# nrf54lv10a_enga_application register map
Vendor: Nordic Semiconductor; Series: nrf54l; File version: 1
CPU: CM33 r0p4, little endian, MPU, FPU, 3 interrupt priority bits, 270 interrupts, 4 SAU regions
Registers are 32-bit, read-write, reset 0x0 unless marked. A register's access mark holds for its fields unless they carry their own. Offsets are from the block's base; [hi:lo] are bit positions; lines under a group give offsets from that group; {n}, {i} and the like mark numbered series; 'fields as' and 'values as' point back to an identical list.

## GLOBAL_ECB00_NS — AES ECB Mode Encryption 0
Base 0x4004B000
Same registers: GLOBAL_ECB00_S 0x5004B000
0x00 TASKS_START wo — Start ECB block encrypt
  [0] TASKS_START
    1=Trigger task
0x04 TASKS_STOP wo — Abort a possible executing ECB operation
  [0] TASKS_STOP
    1=Trigger task
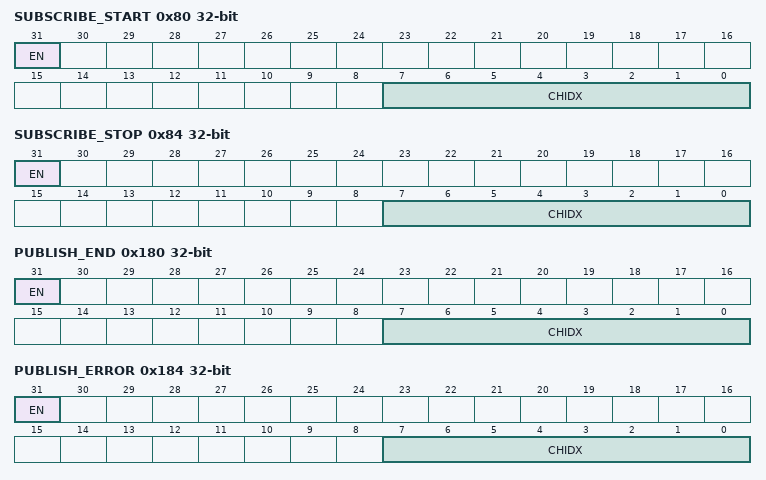
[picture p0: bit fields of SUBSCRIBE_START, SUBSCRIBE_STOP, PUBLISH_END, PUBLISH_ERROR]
0x80 SUBSCRIBE_START — Subscribe configuration for task START
  [31] EN
    0=Disabled (Disable subscription); 1=Enabled (Enable subscription)
  [7:0] CHIDX — DPPI channel that task START will subscribe to
0x84 SUBSCRIBE_STOP — Subscribe configuration for task STOP
  [31] EN
    values as SUBSCRIBE_START.EN
  [7:0] CHIDX — DPPI channel that task STOP will subscribe to
0x100 EVENTS_END — ECB block encrypt complete
  [0] EVENTS_END
    0=NotGenerated (Event not generated); 1=Generated (Event generated)
0x104 EVENTS_ERROR — ECB block encrypt aborted because of a STOP task or due to an error
  [0] EVENTS_ERROR
    values as EVENTS_END.EVENTS_END
0x180 PUBLISH_END — Publish configuration for event END
  [31] EN
    0=Disabled (Disable publishing); 1=Enabled (Enable publishing)
  [7:0] CHIDX — DPPI channel that event END will publish to
0x184 PUBLISH_ERROR — Publish configuration for event ERROR
  [31] EN
    values as PUBLISH_END.EN
  [7:0] CHIDX — DPPI channel that event ERROR will publish to
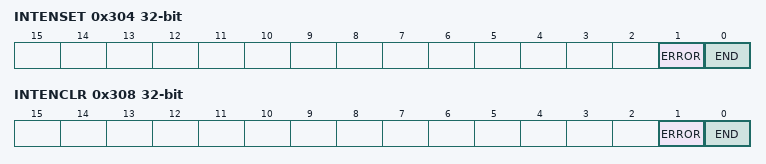
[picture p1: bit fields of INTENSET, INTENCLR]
0x304 INTENSET — Enable interrupt
  [1] ERROR — Write '1' to enable interrupt for event ERROR
    on read: 0=Disabled (Read: Disabled); 1=Enabled (Read: Enabled) | on write: 1=Set (Enable)
  [0] END — Write '1' to enable interrupt for event END
    values as ERROR
0x308 INTENCLR — Disable interrupt
  [1] ERROR — Write '1' to disable interrupt for event ERROR
    on read: 0=Disabled (Read: Disabled); 1=Enabled (Read: Enabled) | on write: 1=Clear (Disable)
  [0] END — Write '1' to disable interrupt for event END
    values as ERROR
0x400 ERRORSTATUS ro
  [2:0] ERRORSTATUS — Error status when the ERROR event is generated
    0=No errors have occurred; 1=PrematureInptrEnd (End of INPTR job list before data structure was read.); 2=PrematureOutptrEnd (End of OUTPTR job list before data structure was read.); 3=EncryptionTooSlow (Deprecated enumerator - Encryption aborted due to higher priority peripheral requesting or using the AES module.); 3=Aborted (Encryption aborted due to higher priority peripheral requesting or using the AES module.); 4=DmaError (Bus error during DMA access.)
0x510 KEY group — Unspecified
  {0x0+4j} VALUE[{j}] (j=0..3) wo — Description collection: 128-bit AES key
    [31:0] VALUE — AES 128-bit key value, bits (32*(n+1))-1 : (32*n)
0x530 IN group — IN EasyDMA channel
  0x00 PTR — Input pointer
    [31:0] PTR — Points to a job list containing unencrypted ECB data structure
0x538 OUT group — OUT EasyDMA channel
  0x00 PTR — Output pointer Points to a job list containing encrypted ECB data structure
    [31:0] PTR — Output pointer
0x53C CSAA group — Channel sounding access address scoring algorithm
  0x00 REFLECTOR ro — Selected Channel Sounding Access Address used in the CS SYNC from Reflector to Initiator
    [31:0] PN
  0x04 INITIATOR ro — Selected Channel Sounding Access Address used in the CS SYNC from Initiator to Reflector
    [31:0] PN
  0x08 MODE — Operation modes
    [0] BITREVERSE — Reverse the endianness on bit level for the ECB output, INITIATOR, and REFLECTOR registers
      0=Default endianness; 1=Reversed endianness

## GLOBAL_GLITCHDET_S — Voltage glitch detectors
Base 0x5004E000
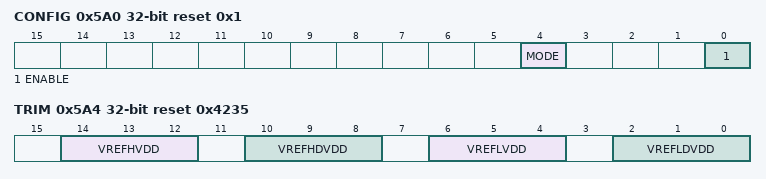
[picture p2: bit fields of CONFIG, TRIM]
0x5A0 CONFIG reset 0x1 — Configuration for glitch detector
  [4] MODE — Glitch detector mode
    0=High pass filter mode; 1=Cap divider mode
  [0] ENABLE — Enable glitch detector
    0=Disable glitch detector; 1=Enable glitch detector
0x5A4 TRIM reset 0x4235 — Trim configuration for glitch detector
  [14:12] VREFHVDD — Voltage trimming value for VREFH_VDD
    0=1V150 (0.150 V); 1=1V175 (0.175 V); 2=1V200 (1.200 V); 3=1V225 (1.225 V); 4=1V250 (1.250 V); 5=1V275 (1.275 V); 6=1V300 (1.300 V); 7=1V325 (1.325 V)
  [10:8] VREFHDVDD — Voltage trimming value for VREFH_DVDD
    0=0V950 (0.950 V); 1=0V975 (0.975 V); 2=1V000 (1.000 V); 3=1V025 (1.025 V); 4=1V050 (1.050 V); 5=1V075 (1.075 V); 6=1V100 (1.100 V); 7=1V125 (1.125 V)
  [6:4] VREFLVDD — Voltage trimming value for VREFL_VDD
    0=0V425 (0.425 V); 1=0V450 (0.450 V); 2=0V475 (0.475 V); 3=0V500 (0.500 V); 4=0V525 (0.525 V); 5=0V550 (0.550 V); 6=0V575 (0.575 V); 7=0V600 (0.600 V)
  [2:0] VREFLDVDD — Voltage trimming value for VREFL_DVDD
    0=0V675 (0.675 V); 1=0V700 (0.700 V); 2=0V725 (0.725 V); 3=0V750 (0.750 V); 4=0V775 (0.775 V); 5=0V800 (0.800 V); 6=0V825 (0.825 V); 7=0V850 (0.850 V)
0x5B0 DFT group — Unspecified
  0x00 ATB0CONFIG — Analog Test Bus 0 (ATB0) configuration
    [2:0] SELMUX — Select multiplexer for ATB0
      0=HiZ (High impedance); 1=VDDDIV (Measure/Force VDD_DIV voltage from external); 2=VDDDIG0V9 (Measure/Force VDD_DIG_0V9 voltage from external); 3=VSS; 4=GLITCHSRVDD3V0 (Internal signal - GLITCH_SR_VDD_3V0)
  0x04 ATB1CONFIG — Analog Test Bus 1 (ATB1) configuration
    [2:0] SELMUX — Select multiplexer for ATB1
      0=HiZ (High impedance); 1=VREFHVDD (Measure VREFH_VDD voltage); 2=VREFLVDD (Measure VREFL_VDD voltage); 3=VREFHDAVDD (Measure VREFH_DVDD voltage); 4=VREFLDVDD (Measure VREFL_DVDD voltage); 5=GLITCHSRDVDD3V0 (Internal signal - GLITCH_SR_DVDD_3V0)
  0x08 ATB2CONFIG — Analog Test Bus 2 (ATB2) configuration
    [1:0] SELMUX — Select multiplexer for ATB2
      0=HiZ (High impedance); 1=VTAMPORDVDD3V0 (Internal signal - VTAMP_OR_DVDD_3V0); 2=VTAMPORVDD3V0 (Internal signal - VTAMP_OR_VDD_3V0); 3=GLITCHNINT3V0 (Internal signal - GLITCH_N_INT_3V0)
